# STM32F40x register map
File version: 1.5
Registers are 32-bit, read-write, reset 0x0 unless marked. A register's access mark holds for its fields unless they carry their own. Offsets are from the block's base; [hi:lo] are bit positions.

## PWR（电源控制） — 电源控制：稳压器/唤醒/备份域访问 | Power control
Base 0x40007000
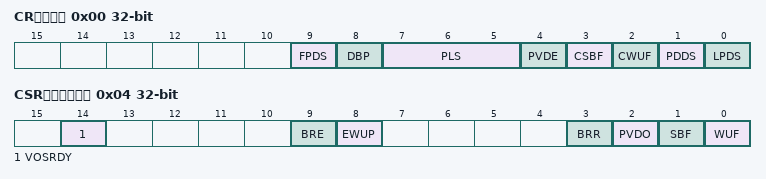
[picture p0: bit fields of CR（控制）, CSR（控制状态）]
0x00 CR（控制） — 控制：稳压器/唤醒/PVD/备份访问 | power control register
  [9] FPDS — Flash power down in Stop mode
  [8] DBP — Disable backup domain write protection
  [7:5] PLS — PVD level selection
  [4] PVDE — Power voltage detector enable
  [3] CSBF — Clear standby flag
  [2] CWUF — Clear wakeup flag
  [1] PDDS — Power down deepsleep
  [0] LPDS — Low-power deep sleep
0x04 CSR（控制状态） access per field — 控制状态：PVD 输出/唤醒/待机标志 | power control/status register
  [14] VOSRDY rw — Regulator voltage scaling output selection ready bit
  [9] BRE rw — Backup regulator enable
  [8] EWUP rw — Enable WKUP pin
  [3] BRR ro — Backup regulator ready
  [2] PVDO ro — PVD output
  [1] SBF ro — Standby flag
  [0] WUF ro — Wakeup flag

## I2C3（集成电路总线） — 集成电路总线：双线制串行通信 | Inter-integrated circuit
Base 0x40005C00
Same registers: I2C1（集成电路总线） 0x40005400, I2C2（集成电路总线） 0x40005800
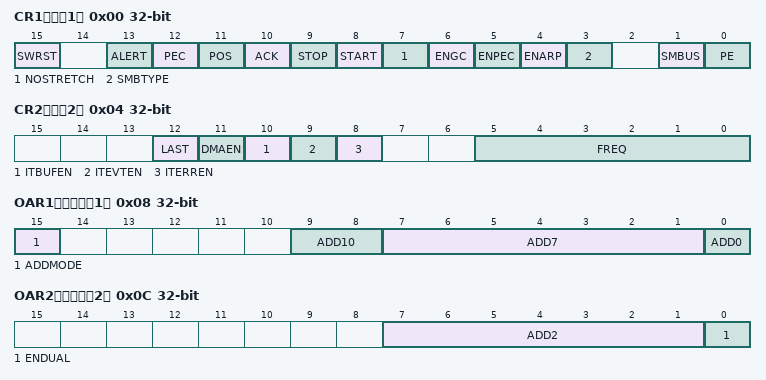
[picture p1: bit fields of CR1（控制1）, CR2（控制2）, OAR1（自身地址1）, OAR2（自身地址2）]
0x00 CR1（控制1） — 控制1：使能/时钟延长/中断 | Control register 1
  [15] SWRST — Software reset
  [13] ALERT — SMBus alert
  [12] PEC — Packet error checking
  [11] POS — Acknowledge/PEC Position (for data reception)
  [10] ACK — Acknowledge enable
  [9] STOP — Stop generation
  [8] START — Start generation
  [7] NOSTRETCH — Clock stretching disable (Slave mode)
  [6] ENGC — General call enable
  [5] ENPEC — PEC enable
  [4] ENARP — ARP enable
  [3] SMBTYPE — SMBus type
  [1] SMBUS — SMBus mode
  [0] PE — Peripheral enable
0x04 CR2（控制2） — 控制2：外设时钟频率/中断/DMA 触发 | Control register 2
  [12] LAST — DMA last transfer
  [11] DMAEN — DMA requests enable
  [10] ITBUFEN — Buffer interrupt enable
  [9] ITEVTEN — Event interrupt enable
  [8] ITERREN — Error interrupt enable
  [5:0] FREQ — Peripheral clock frequency
0x08 OAR1（自身地址1） — 自身地址 1（7/10 位） | Own address register 1
  [15] ADDMODE — Addressing mode (slave mode)
  [9:8] ADD10 — Interface address
  [7:1] ADD7 — Interface address
  [0] ADD0 — Interface address
0x0C OAR2（自身地址2） — 自身地址 2（仅 7 位） | Own address register 2
  [7:1] ADD2 — Interface address
  [0] ENDUAL — Dual addressing mode enable
0x10 DR（数据） — 数据：收发数据 | Data register
  [7:0] DR — 8-bit data register
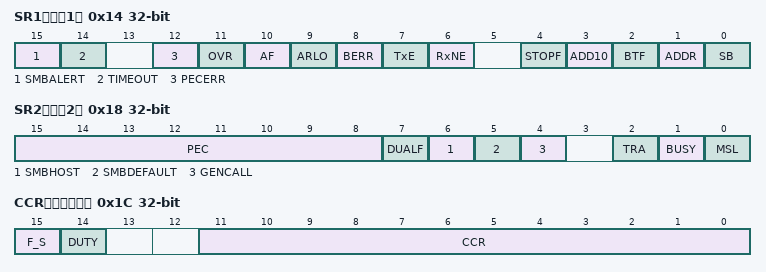
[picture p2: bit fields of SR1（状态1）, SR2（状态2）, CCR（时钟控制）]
0x14 SR1（状态1） access per field — 状态1：状态与错误标志 | Status register 1
  [15] SMBALERT rw — SMBus alert
  [14] TIMEOUT rw — Timeout or Tlow error
  [12] PECERR rw — PEC Error in reception
  [11] OVR rw — Overrun/Underrun
  [10] AF rw — Acknowledge failure
  [9] ARLO rw — Arbitration lost (master mode)
  [8] BERR rw — Bus error
  [7] TxE ro — Data register empty (transmitters)
  [6] RxNE ro — Data register not empty (receivers)
  [4] STOPF ro — Stop detection (slave mode)
  [3] ADD10 ro — 10-bit header sent (Master mode)
  [2] BTF ro — Byte transfer finished
  [1] ADDR ro — Address sent (master mode)/matched (slave mode)
  [0] SB ro — Start bit (Master mode)
0x18 SR2（状态2） ro — 状态2：地址/总线状态标志 | Status register 2
  [15:8] PEC — acket error checking register
  [7] DUALF — Dual flag (Slave mode)
  [6] SMBHOST — SMBus host header (Slave mode)
  [5] SMBDEFAULT — SMBus device default address (Slave mode)
  [4] GENCALL — General call address (Slave mode)
  [2] TRA — Transmitter/receiver
  [1] BUSY — Bus busy
  [0] MSL — Master/slave
0x1C CCR（时钟控制） — 时钟控制：标准/快速模式频率 | Clock control register
  [15] F_S — I2C master mode selection
  [14] DUTY — Fast mode duty cycle
  [11:0] CCR — Clock control register in Fast/Standard mode (Master mode)
0x20 TRISE（上升时间） reset 0x2 — 上升时间：最大上升时间配置 | TRISE register
  [5:0] TRISE — Maximum rise time in Fast/Standard mode (Master mode)

## IWDG（独立看门狗） — 独立看门狗：超时复位（独立时钟） | Independent watchdog
Base 0x40003000
0x00 KR（密钥） wo — 密钥：喂狗/启动/写保护 | Key register
  [15:0] KEY — Key value (write only, read 0000h)
0x04 PR（预分频） — 看门狗时钟预分频 | Prescaler register
  [2:0] PR — Prescaler divider
0x08 RLR（重装载） reset 0xFFF — 重装载值（超时） | Reload register
  [11:0] RL — Watchdog counter reload value
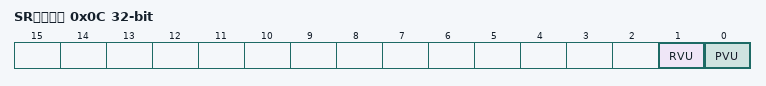
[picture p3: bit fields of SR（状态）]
0x0C SR（状态） ro — 状态：看门狗更新状态 | Status register
  [1] RVU — Watchdog counter reload value update
  [0] PVU — Watchdog prescaler value update
